# nrf54h20_engb_secure register map
Vendor: Nordic Semiconductor; Series: nRF54h; File version: 1
CPU: CM33 r0p4, little endian, MPU, no FPU, 3 interrupt priority bits, 480 interrupts, 8 SAU regions
Registers are 32-bit, read-write, reset 0x0 unless marked. A register's access mark holds for its fields unless they carry their own. Offsets are from the block's base; [hi:lo] are bit positions; lines under a group give offsets from that group; {n}, {i} and the like mark numbered series; 'fields as' and 'values as' point back to an identical list.

## SWI0_NS — Software interrupt 0
Base 0x42058000
Same registers: SWI1_NS 0x42059000, SWI2_NS 0x4205A000, SWI3_NS 0x4205B000, SWI4_NS 0x4205C000, SWI5_NS 0x4205D000, SWI6_NS 0x4205E000, SWI7_NS 0x4205F000

## BELLBOARD_NS — BELLBOARD APB registers 0
Base 0x4F099000
Same registers: BELLBOARD_S 0x5F099000
{0x0+4i} TASKS_TRIGGER[{i}] (i=0..31) wo — Description collection: Task TRIGGER[n]
  [0] TASKS_TRIGGER — Task TRIGGER[n]
    1=Trigger task
{0x100+4i} EVENTS_TRIGGERED[{i}] (i=0..31) — Description collection: Event TRIGGERED[n]
  [0] EVENTS_TRIGGERED — Event TRIGGERED[n]
    0=NotGenerated (Event not generated); 1=Generated (Event generated)
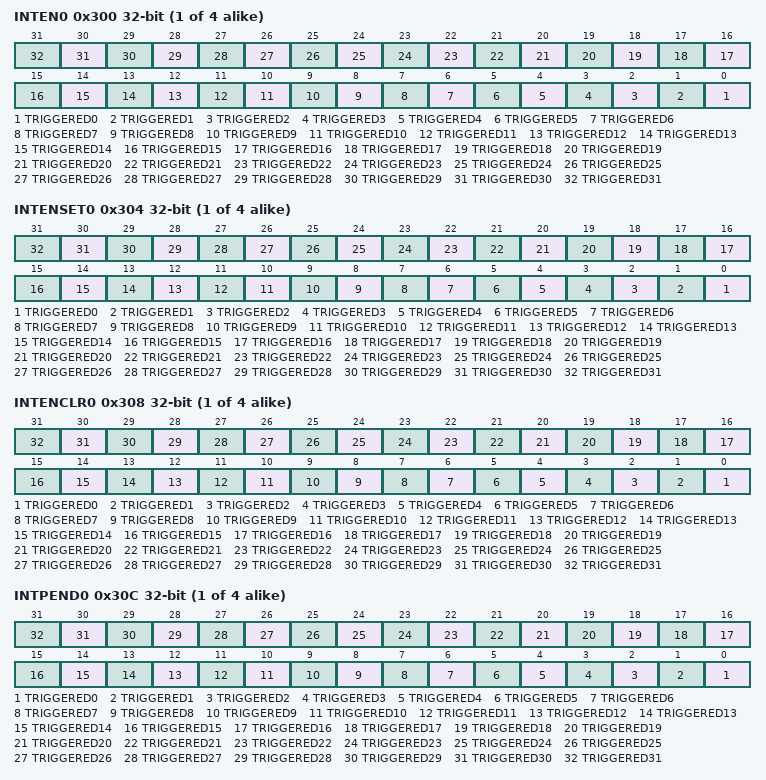
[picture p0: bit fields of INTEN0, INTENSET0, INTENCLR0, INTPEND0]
{0x300+0x10*i} INTEN{i} (i=0..3) — Enable or disable interrupt
  [all] fields
    0=Disabled; 1=Enabled
  [n] TRIGGERED{n} (n=0..31) — Enable or disable interrupt for event TRIGGERED[{n}]
{0x304+0x10*i} INTENSET{i} (i=0..3) — Enable interrupt
  [all] fields
    on read: 0=Disabled (Read: Disabled); 1=Enabled (Read: Enabled) | on write: 1=Set (Enable)
  [n] TRIGGERED{n} (n=0..31) — Write '1' to enable interrupt for event TRIGGERED[{n}]
{0x308+0x10*i} INTENCLR{i} (i=0..3) — Disable interrupt
  [all] fields
    on read: 0=Disabled (Read: Disabled); 1=Enabled (Read: Enabled) | on write: 1=Clear (Disable)
  [n] TRIGGERED{n} (n=0..31) — Write '1' to disable interrupt for event TRIGGERED[{n}]
{0x30C+0x10*i} INTPEND{i} ro (i=0..3) — Pending interrupts
  [all] fields
    on read: 0=NotPending (Read: Not pending); 1=Pending (Read: Pending)
  [n] TRIGGERED{n} (n=0..31) — Read pending status of interrupt for event TRIGGERED[{n}]

## CTRLAP_NS — Control access port
Base 0xBF015000
0x100 EVENTS_RXREADY — The RXSTATUS is changed to DataPending
  [0] EVENTS_RXREADY
    0=NotGenerated (Event not generated); 1=Generated (Event generated)
0x104 EVENTS_TXDONE — The TXSTATUS is changed to NoDataPending
  [0] EVENTS_TXDONE
    values as EVENTS_RXREADY.EVENTS_RXREADY
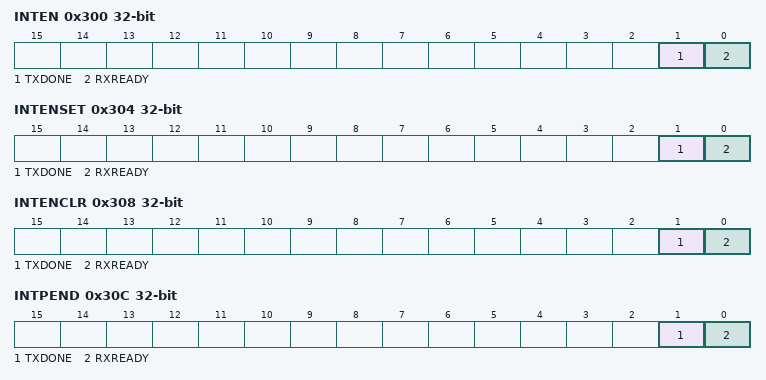
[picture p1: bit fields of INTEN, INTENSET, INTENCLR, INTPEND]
0x300 INTEN — Enable or disable interrupt
  [1] TXDONE — Enable or disable interrupt for event TXDONE
    0=Disabled; 1=Enabled
  [0] RXREADY — Enable or disable interrupt for event RXREADY
    0=Disabled; 1=Enabled
0x304 INTENSET — Enable interrupt
  [1] TXDONE — Write '1' to enable interrupt for event TXDONE
    on read: 0=Disabled (Read: Disabled); 1=Enabled (Read: Enabled) | on write: 1=Set (Enable)
  [0] RXREADY — Write '1' to enable interrupt for event RXREADY
    values as TXDONE
0x308 INTENCLR — Disable interrupt
  [1] TXDONE — Write '1' to disable interrupt for event TXDONE
    on read: 0=Disabled (Read: Disabled); 1=Enabled (Read: Enabled) | on write: 1=Clear (Disable)
  [0] RXREADY — Write '1' to disable interrupt for event RXREADY
    values as TXDONE
0x30C INTPEND ro — Pending interrupts
  [1] TXDONE — Read pending status of interrupt for event TXDONE
    on read: 0=NotPending (Read: Not pending); 1=Pending (Read: Pending)
  [0] RXREADY — Read pending status of interrupt for event RXREADY
    values as TXDONE
0x400 MAILBOX group — Unspecified
  0x00 RXDATA ro — Data sent from the debugger to the CPU
    [31:0] RXDATA — Data received from debugger
  0x04 RXSTATUS ro — Status to indicate if data sent from the debugger to the CPU has been read
    [0] RXSTATUS — Status of data in register RXDATA
      0=No data pending in register RXDATA; 1=Data pending in register RXDATA
  0x80 TXDATA — Data sent from the CPU to the debugger
    [31:0] TXDATA — Data sent to debugger
  0x84 TXSTATUS ro — Status to indicate if data sent from the CPU to the debugger has been read
    [0] TXSTATUS — Status of data in register TXDATA
      0=No data pending in register TXDATA; 1=Data pending in register TXDATA
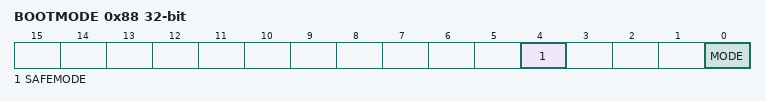
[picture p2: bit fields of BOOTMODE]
  0x88 BOOTMODE ro — Secure domain boot mode.
    [4] SAFEMODE — Secure domain safe boot mode
      0=Normal mode of operation; 1=Safe operation mode
    [0] MODE
      0=Normal mode of operation; 1=ROM operation mode
0x500 INFO group — Unspecified
  0x00 PARTNO — Part number of the device
    [11:0] PARTNO — Part number
  0x04 HWREVISION — Hardware Revision of the device
    [3:0] ID — Part Variant
  0x08 READY reset 0x1 — Ready status.
    [0] READY
      0=Ready; 1=NotReady
0x50C BOOTSTATUS
  [31:0] VAL — Value
